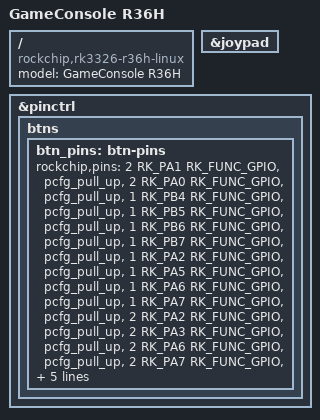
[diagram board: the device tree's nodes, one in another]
// SPDX-License-Identifier: (GPL-2.0+ OR MIT)
/*
* Copyright (c) 2026 kk&lcdyk
*
* GameConsole R36H
*
*/

/dts-v1/;
#include "rk3326-r36s-panel4-type1-linux.dts"

/ {
	model = "GameConsole R36H";
	compatible = "rockchip,rk3326-r36h-linux", "rockchip,rk3326";
};

&joypad {
	/delete-node/ sw13;
};

&pinctrl {
	btns {
		btn_pins: btn-pins {
			rockchip,pins =
			<2 RK_PA1 RK_FUNC_GPIO &pcfg_pull_up>,
			<2 RK_PA0 RK_FUNC_GPIO &pcfg_pull_up>,
			<1 RK_PB4 RK_FUNC_GPIO &pcfg_pull_up>,
			<1 RK_PB5 RK_FUNC_GPIO &pcfg_pull_up>,
			<1 RK_PB6 RK_FUNC_GPIO &pcfg_pull_up>,
			<1 RK_PB7 RK_FUNC_GPIO &pcfg_pull_up>,
			<1 RK_PA2 RK_FUNC_GPIO &pcfg_pull_up>,
			<1 RK_PA5 RK_FUNC_GPIO &pcfg_pull_up>,
			<1 RK_PA6 RK_FUNC_GPIO &pcfg_pull_up>,
			<1 RK_PA7 RK_FUNC_GPIO &pcfg_pull_up>,
			<2 RK_PA2 RK_FUNC_GPIO &pcfg_pull_up>,
			<2 RK_PA3 RK_FUNC_GPIO &pcfg_pull_up>,
			<2 RK_PA6 RK_FUNC_GPIO &pcfg_pull_up>,
			<2 RK_PA7 RK_FUNC_GPIO &pcfg_pull_up>,
			<3 RK_PB1 RK_FUNC_GPIO &pcfg_pull_up>,
			<3 RK_PB7 RK_FUNC_GPIO &pcfg_pull_up>,
			<3 RK_PB2 RK_FUNC_GPIO &pcfg_pull_up>,
			<3 RK_PB4 RK_FUNC_GPIO &pcfg_pull_up>;
		};
	};
};

/* DON'T PUT ANYTHING BELOW HERE.  PUT IT ABOVE PINCTRL */

